# T113-S3 register map
Vendor: Allwinner; Series: T113-S3; File version: 0.1
CPU: other 0, little endian, MPU, no FPU, 0 interrupt priority bits
Registers are 32-bit, read-write, reset 0x0 unless marked. A register's access mark holds for its fields unless they carry their own. Offsets are from the block's base; [hi:lo] are bit positions; {n}, {i} and the like mark numbered series; 'fields as' and 'values as' point back to an identical list; <NAME> marks a mode.

## Audio_Codec (part 3 of 3)
Base 0x02030000
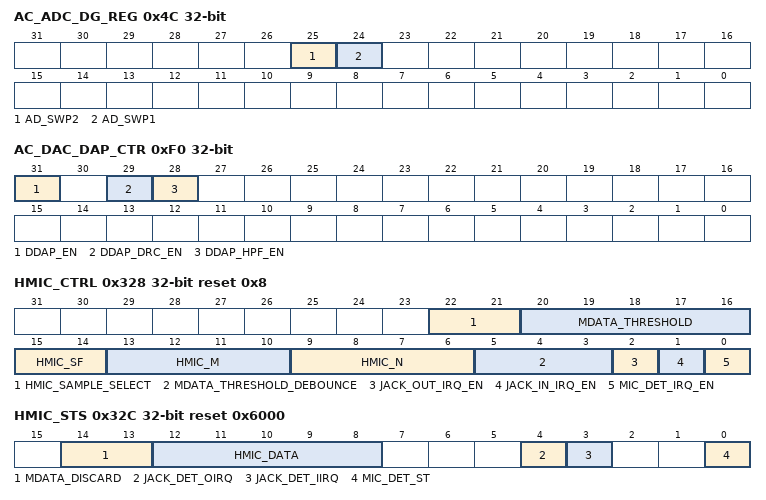
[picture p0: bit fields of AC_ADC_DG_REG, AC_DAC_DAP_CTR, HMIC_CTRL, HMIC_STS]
0x4C AC_ADC_DG_REG
  [25] AD_SWP2 — ADC output channel swap enable (for digital filter) 0: Disabled 1: Enabled
    0=Disabled; 1=Enabled
  [24] AD_SWP1 — ADC output channel swap enable (for digital filter) 0: Disabled 1: Enabled
    0=Disabled; 1=Enabled
0xF0 AC_DAC_DAP_CTR
  [31] DDAP_EN — DAP for DRC enable 0: Bypassed 1: Enabled
    0=Bypassed; 1=Enabled
  [29] DDAP_DRC_EN — DRC enable control 0: Disabled 1: Enabled
    0=Disabled; 1=Enabled
  [28] DDAP_HPF_EN — HPF enable control 0: Disabled 1: Enabled
    0=Disabled; 1=Enabled
0x2A4 AC_ADC_DRC_MNGHS reset 0xF95B
  [15:0] ADC_DRC_MNGHS — The min gain setting, which is determined by equation MXG =MXG/6.0206. The format is 8.24 and must -60 dB <= MNG <= -40 dB (The default value is -40 dB)
0x328 HMIC_CTRL reset 0x8
  [22:21] HMIC_SAMPLE_SELECT — Down Sample Setting Select 00: Down by 1, 128 Hz 01: Down by 2, 64 Hz 10: Down by 4, 32 Hz 11: Down by 8, 16 Hz
    0=Down by 1, 128 Hz; 1=Down by 2, 64 Hz; 2=Down by 4, 32 Hz; 3=Down by 8, 16 Hz
  [20:16] MDATA_THRESHOLD — MIC DET EN Threshold Value
  [15:14] HMIC_SF — HMIC Smooth Filter setting 00: by pass 01: (x1+x2)/2 10: (x1+x2+x3+x4)/4 11: (x1+x2+x3+x4+ x5+x6+x7+x8)/8
    0=by (by pass); 1=_openingparen_x1_plus_x2_closingparen__slash_2 ((x1+x2)/2); 2=_openingparen_x1_plus_x2_plus_x3_plus_x4_closingparen__slash_4 ((x1+x2+x3+x4)/4); 3=_openingparen_x1_plus_x2_plus_x3_plus_x4_plus_ ((x1+x2+x3+x4+ x5+x6+x7+x8)/8)
  [13:10] HMIC_M — Debounce when the MIC Key down or up. 0000 :1 samlpe data 0001 :2 samlpe data ... 1111 :16 samlpe data
  [9:6] HMIC_N — Debounce when earphone plug in or pull out 125 ms to 2 s 0000:125 ms 0001:250 ms ... 1111:2 s
  [5:3] MDATA_THRESHOLD_DEBOUNCE — MDATA Threshold Debounce 000: 0 001: 1 010: 2 011: 3 100: 4 101: 5 110: 6 111: 7
  [2] JACK_OUT_IRQ_EN — MIC Detect Interrupt Set 0: Disabled 1: Enabled
    0=Disabled; 1=Enabled
  [1] JACK_IN_IRQ_EN — MIC Detect Interrupt Set 0: Disabled 1: Enabled
    0=Disabled; 1=Enabled
  [0] MIC_DET_IRQ_EN — MIC Detect Interrupt Set 0: Disabled 1: Enabled
    0=Disabled; 1=Enabled
0x32C HMIC_STS reset 0x6000
  [14:13] MDATA_DISCARD — After MIC DATA data is received, the first N-data will be discarded. N defined as follows: 00: None discarded 01: 1-data discarded 10: 2-data discarded 11: 4-data discarded
    0=None discarded; 1=_1_minus_data (1-data discarded); 2=_2_minus_data (2-data discarded); 3=_4_minus_data (4-data discarded)
  [12:8] HMIC_DATA ro — HMIC Average Data
  [4] JACK_DET_OIRQ write-1-clears — Jack output detect pending interrupt 0: No Pending IRQ 1: Pending IRQ Writing 1 clear pending.
    0=No Pending IRQ; 1=Pending IRQ Writing 1 clear pending
  [3] JACK_DET_IIRQ write-1-clears — Jack input detect pending interrupt 0: No Pending IRQ 1: Pending IRQ Writing 1 clear pending.
    0=No Pending IRQ; 1=Pending IRQ Writing 1 clear pending
  [0] MIC_DET_ST write-1-clears — MIC detect pending interrupt 0: No pending IRQ 1: Pending IRQ Writing 1 clear pending.
    0=No pending IRQ; 1=Pending IRQ Writing 1 clear pending
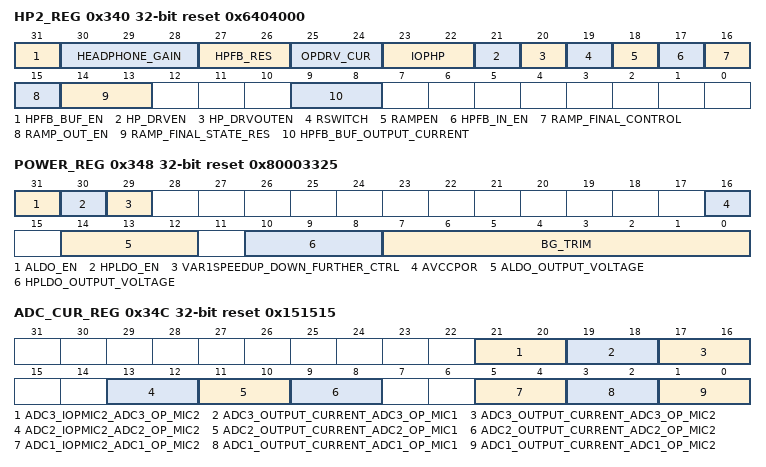
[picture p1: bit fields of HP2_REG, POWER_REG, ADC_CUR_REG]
0x340 HP2_REG reset 0x6404000
  [31] HPFB_BUF_EN — Headphone Feedback Buffer OP Enable 0: Disable 1: Enable
    0=Disable; 1=Enable
  [30:28] HEADPHONE_GAIN — HeadPhone Gain 000: 0 dB 001: -6 dB 010: -12 dB 011: -18 dB 100: -24 dB 101: -30 dB 110: -36 dB 111: -42 dB
    0=_0_dB; 1=_minus_6_dB (-6 dB); 2=_minus_12_dB (-12 dB); 3=_minus_18_dB (-18 dB); 4=_minus_24_dB (-24 dB); 5=_minus_30_dB (-30 dB); 6=_minus_36_dB (-36 dB); 7=_minus_42_dB (-42 dB)
  [27:26] HPFB_RES — Headphone Feedback Big Resistor Control 00: 0.88 MΩ 01: 1.00 MΩ 10: 1.08 MΩ 11: 1.20 MΩ
    0=_0_point_88 (0.88 MΩ); 1=_1_point_00 (1.00 MΩ); 2=_1_point_08 (1.08 MΩ); 3=_1_point_20 (1.20 MΩ)
  [25:24] OPDRV_CUR — Headphone OP Output Stage Current Setting 00: Min 11: Max
    0=Min; 3=Max
  [23:22] IOPHP — Headphone L/R OP Bias Current Select 00: 6 uA 01: 7 uA 10: 8 uA 11: 9 uA
    {v}=_{v+6}_uA (v=0..3)
  [21] HP_DRVEN — Headphone Driver Enable 0: Disable 1: Enable
    0=Disable; 1=Enable
  [20] HP_DRVOUTEN — Headphone Driver Output Enable 0: Disabled 1: Enabled
    0=Disabled; 1=Enabled
  [19] RSWITCH — RSwitch 0: HPOUT OUTPUT VCM of RAMP_DAC 1: VRA1
    0=HPOUT (HPOUT OUTPUT VCM of RAMP_DAC); 1=VRA1
  [18] RAMPEN — Ramp DAC Enable 0: Disabled 1: Enabled
    0=Disabled; 1=Enabled
  [17] HPFB_IN_EN — Headphone Feedback PAD IN Switch Enable 0: Disabled 1: Enabled
    0=Disabled; 1=Enabled
  [16] RAMP_FINAL_CONTROL — Headphone Ramp Final Step Control 0: Ramp Output Select Ramp 1: Ramp Output Select HPFB buffer Output
    0=Ramp_Output_Select_Ramp; 1=Ramp Output Select HPFB buffer Output
  [15] RAMP_OUT_EN — Ramp Output Switch Enable 0: Disable 1: Enable
    0=Disable; 1=Enable
  [14:13] RAMP_FINAL_STATE_RES — Ramp Final State Resistor 00: 2.5k 01: 5.0k 10: 10k 11: 20k
    0=_2_point_5k (2.5k); 1=_5_point_0k (5.0k); 2=_10k; 3=_20k
  [9:8] HPFB_BUF_OUTPUT_CURRENT — Headphone Feedback Buffer Output Current Select 00: 35I 01: 28I 10: 45I 11: 38I I=7 uA
    0=_35I; 1=_28I; 2=_45I; 3=_38I (38I I=7 uA)
0x348 POWER_REG reset 0x80003325
  [31] ALDO_EN — ALDO Enable 0: Disabled 1: Enabled
    0=Disabled; 1=Enabled
  [30] HPLDO_EN — HPLDO Enable 0: Disabled 1: Enabled
    0=Disabled; 1=Enabled
  [29] VAR1SPEEDUP_DOWN_FURTHER_CTRL — VAR1 Speedup Down Further Control In Adda Analog 0: The digital logic signal input by the digital-analog interface pin controls the var1_speedup_down function (that is, the var1 signal is rapidly pulled up/down) 1: Writing 1 can finish the var1_speedup_down function (ignore the control of the digital-analog interface pin)
    0=digital (The digital logic signal input by the digital-analog interface pin controls the var1_speedup_down function (that is, the var1 signal is rapidly pulled up/down)); 1=Writing 1 can finish the var1_speedup_down function (ignore the control of the digital-analog interface pin)
  [16] AVCCPOR ro — Avccpor Monitor
  [14:12] ALDO_OUTPUT_VOLTAGE — ALDO Output Voltage Control 000: 2.03 V 001: 1.95 V 010: 1.87 V 011: 1.80 V 100: 1.73 V 101: 1.67 V 110: 1.61 V 111: 1.56 V
    0=_2_point_03_V (2.03 V); 1=_1_point_95_V (1.95 V); 2=_1_point_87_V (1.87 V); 3=_1_point_80_V (1.80 V); 4=_1_point_73_V (1.73 V); 5=_1_point_67_V (1.67 V); 6=_1_point_61_V (1.61 V); 7=_1_point_56_V (1.56 V)
  [10:8] HPLDO_OUTPUT_VOLTAGE — HPLDO Output Voltage Control 000: 2.03 V 001: 1.95 V 010: 1.87 V 011: 1.80 V 100: 1.73 V 101: 1.67 V 110: 1.61 V 111: 1.56 V
    values as ALDO_OUTPUT_VOLTAGE
  [7:0] BG_TRIM — BG Output Voltage Trimming Only low 6-bit is used. The BG output voltage range is from 0.7 V to 1.208 V.
0x34C ADC_CUR_REG reset 0x151515
  [21:20] ADC3_IOPMIC2_ADC3_OP_MIC2 — ADC3_IOPMIC2 ADC3 OP MIC2 Bias Current Select 00: 1.50*IOPADC 01: 1.75*IOPADC 10: 2.00*IOPADC 11: 2.25*IOPADC IOPADC is defined by ADC1_REG<15:14> from 1 uA to 4 uA
    0=_1_point_50_times_IOPADC (1.50*IOPADC); 1=_1_point_75_times_IOPADC (1.75*IOPADC); 2=_2_point_00_times_IOPADC (2.00*IOPADC); 3=_2_point_25_times_IOPADC (2.25*IOPADC IOPADC is defined by ADC1_REG<15:14> from 1 uA to 4 uA)
  [19:18] ADC3_OUTPUT_CURRENT_ADC3_OP_MIC1 — ADC3_OUTPUT_CURRENT ADC3 OP MIC1 Output Current Select 00: 15I 01: 20I 10: 35I 11: 40I I=7 uA
    0=_15I; 1=_20I; 2=_35I; 3=_40I (40I I=7 uA)
  [17:16] ADC3_OUTPUT_CURRENT_ADC3_OP_MIC2 — ADC3_OUTPUT_CURRENT ADC3 OP MIC2 Output Current Select 00: 15I 01: 20I 10: 35I 11: 40I I=7 uA
    0=_15I; 1=_20I; 2=_35I; 3=_40I (40I I=7 uA)
  [13:12] ADC2_IOPMIC2_ADC2_OP_MIC2 — ADC2_IOPMIC2 ADC2 OP MIC2 Bias Current Select 00: 1.50*IOPADC 01: 1.75*IOPADC 10: 2.00*IOPADC 11: 2.25*IOPADC IOPADC is defined by ADC1_REG<15:14> from 1 uA to 4 uA.
    0=_1_point_50_times_IOPADC (1.50*IOPADC); 1=_1_point_75_times_IOPADC (1.75*IOPADC); 2=_2_point_00_times_IOPADC (2.00*IOPADC); 3=_2_point_25_times_IOPADC (2.25*IOPADC IOPADC is defined by ADC1_REG<15:14> from 1 uA to 4 uA.)
  [11:10] ADC2_OUTPUT_CURRENT_ADC2_OP_MIC1 — ADC2_OUTPUT_CURRENT ADC2 OP MIC1 Output Current Select 00: 15I 01: 20I 10: 35I 11: 40I I=7 uA
    0=_15I; 1=_20I; 2=_35I; 3=_40I (40I I=7 uA)
  [9:8] ADC2_OUTPUT_CURRENT_ADC2_OP_MIC2 — ADC2_OUTPUT_CURRENT ADC2 OP MIC2 Output Current Select 00: 15I 01: 20I 10: 35I 11: 40I I=7 uA
    0=_15I; 1=_20I; 2=_35I; 3=_40I (40I I=7 uA)
  [5:4] ADC1_IOPMIC2_ADC1_OP_MIC2 — ADC1_IOPMIC2 ADC1 OP MIC2 Bias Current Select 00: 1.50*IOPADC 01: 1.75*IOPADC 10: 2.00*IOPADC 11: 2.25*IOPADC IOPADC is defined by ADC1_REG<15:14> from 1 uA to 4 uA.
    values as ADC2_IOPMIC2_ADC2_OP_MIC2
  [3:2] ADC1_OUTPUT_CURRENT_ADC1_OP_MIC1 — ADC1_OUTPUT_CURRENT ADC1 OP MIC1 Output Current Select 00: 15I 01: 20I 10: 35I 11: 40I I=7 uA
    0=_15I; 1=_20I; 2=_35I; 3=_40I (40I I=7 uA)
  [1:0] ADC1_OUTPUT_CURRENT_ADC1_OP_MIC2 — ADC1_OUTPUT_CURRENT ADC1 OP MIC2 Output Current Select 00: 15I 01: 20I 10: 35I 11: 40I I=7 uA
    0=_15I; 1=_20I; 2=_35I; 3=_40I (40I I=7 uA)
